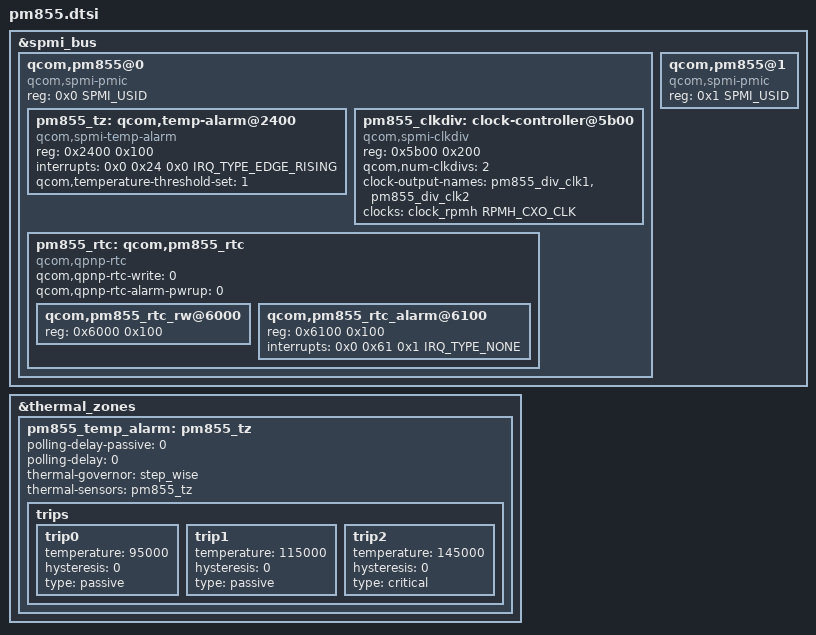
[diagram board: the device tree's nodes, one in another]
/*
 * Copyright (c) 2017-2018, The Linux Foundation. All rights reserved.
 *
 * This program is free software; you can redistribute it and/or modify
 * it under the terms of the GNU General Public License version 2 and
 * only version 2 as published by the Free Software Foundation.
 *
 * This program is distributed in the hope that it will be useful,
 * but WITHOUT ANY WARRANTY; without even the implied warranty of
 * MERCHANTABILITY or FITNESS FOR A PARTICULAR PURPOSE.  See the
 * GNU General Public License for more details.
 */

#include <dt-bindings/spmi/spmi.h>
#include <dt-bindings/interrupt-controller/irq.h>

&spmi_bus {
	qcom,pm855@0 {
		compatible = "qcom,spmi-pmic";
		reg = <0x0 SPMI_USID>;
		#address-cells = <2>;
		#size-cells = <0>;

		pm855_tz: qcom,temp-alarm@2400 {
			compatible = "qcom,spmi-temp-alarm";
			reg = <0x2400 0x100>;
			interrupts = <0x0 0x24 0x0 IRQ_TYPE_EDGE_RISING>;
			#thermal-sensor-cells = <0>;
			qcom,temperature-threshold-set = <1>;
		};

		pm855_clkdiv: clock-controller@5b00 {
			compatible = "qcom,spmi-clkdiv";
			reg = <0x5b00 0x200>;
			#clock-cells = <1>;
			qcom,num-clkdivs = <2>;
			clock-output-names = "pm855_div_clk1", "pm855_div_clk2";
			clocks = <&clock_rpmh RPMH_CXO_CLK>;
			clock-names = "xo";
		};

		pm855_rtc: qcom,pm855_rtc {
			compatible = "qcom,qpnp-rtc";
			#address-cells = <1>;
			#size-cells = <1>;
			qcom,qpnp-rtc-write = <0>;
			qcom,qpnp-rtc-alarm-pwrup = <0>;

			qcom,pm855_rtc_rw@6000 {
				reg = <0x6000 0x100>;
			};
			qcom,pm855_rtc_alarm@6100 {
				reg = <0x6100 0x100>;
				interrupts = <0x0 0x61 0x1 IRQ_TYPE_NONE>;
			};
		};
	};

	qcom,pm855@1 {
		compatible ="qcom,spmi-pmic";
		reg = <0x1 SPMI_USID>;
		#address-cells = <2>;
		#size-cells = <0>;
	};
};

&thermal_zones {
	pm855_temp_alarm: pm855_tz {
		polling-delay-passive = <0>;
		polling-delay = <0>;
		thermal-governor = "step_wise";
		thermal-sensors = <&pm855_tz>;

		trips {
			trip0 {
				temperature = <95000>;
				hysteresis = <0>;
				type = "passive";
			};
			trip1 {
				temperature = <115000>;
				hysteresis = <0>;
				type = "passive";
			};
			trip2 {
				temperature = <145000>;
				hysteresis = <0>;
				type = "critical";
			};
		};
	};
};
